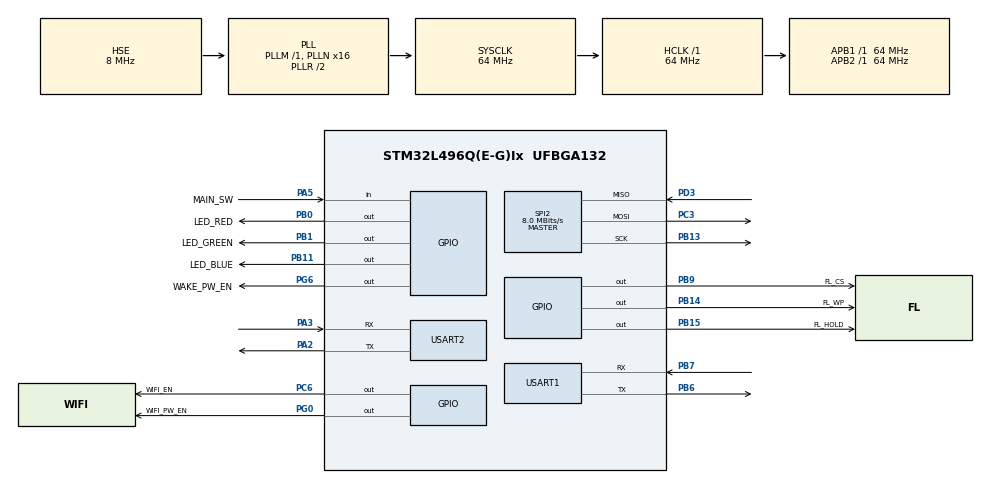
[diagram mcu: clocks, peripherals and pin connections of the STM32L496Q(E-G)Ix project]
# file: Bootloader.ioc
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Mcu.Family=STM32L4
Mcu.Name=STM32L496Q(E-G)Ix
Mcu.Package=UFBGA132
NVIC.PriorityGroup=NVIC_PRIORITYGROUP_4
NVIC.USART2_IRQn=true\:0\:0\:false\:false\:true\:true\:true\:true
PA13\ (JTMS/SWDIO).Mode=Serial_Wire
PA13\ (JTMS/SWDIO).Signal=SYS_JTMS-SWDIO
PA14\ (JTCK/SWCLK).Mode=Serial_Wire
PA14\ (JTCK/SWCLK).Signal=SYS_JTCK-SWCLK
PA2.Mode=Asynchronous
PA2.Signal=USART2_TX
PA3.Mode=Asynchronous
PA3.Signal=USART2_RX
PA5.GPIO_Label=MAIN_SW
PA5.Signal=GPIO_Input
PB0.GPIO_Label=LED_RED
PB0.Signal=GPIO_Output
PB1.GPIO_Label=LED_GREEN
PB1.Signal=GPIO_Output
PB11.GPIO_Label=LED_BLUE
PB11.GPIO_PuPd=GPIO_NOPULL
PB11.Signal=GPIO_Output
PB13.Mode=Full_Duplex_Master
PB13.Signal=SPI2_SCK
PB14.GPIO_Label=FL_WP
PB14.GPIO_PuPd=GPIO_PULLUP
PB14.GPIO_Speed=GPIO_SPEED_FREQ_HIGH
PB14.PinState=GPIO_PIN_SET
PB14.Signal=GPIO_Output
PB15.GPIO_Label=FL_HOLD
PB15.GPIO_PuPd=GPIO_PULLUP
PB15.GPIO_Speed=GPIO_SPEED_FREQ_HIGH
PB15.PinState=GPIO_PIN_SET
PB15.Signal=GPIO_Output
PB6.Mode=Asynchronous
PB6.Signal=USART1_TX
PB7.Mode=Asynchronous
PB7.Signal=USART1_RX
PB9.GPIO_Label=FL_CS
PB9.GPIO_PuPd=GPIO_PULLUP
PB9.GPIO_Speed=GPIO_SPEED_FREQ_HIGH
PB9.PinState=GPIO_PIN_SET
PB9.Signal=GPIO_Output
PC14-OSC32_IN\ (PC14).Mode=LSE-External-Oscillator
PC14-OSC32_IN\ (PC14).Signal=RCC_OSC32_IN
PC15-OSC32_OUT\ (PC15).Mode=LSE-External-Oscillator
PC15-OSC32_OUT\ (PC15).Signal=RCC_OSC32_OUT
PC3.Mode=Full_Duplex_Master
PC3.Signal=SPI2_MOSI
PC6.GPIO_Label=WIFI_EN
PC6.Signal=GPIO_Output
PD3.Mode=Full_Duplex_Master
PD3.Signal=SPI2_MISO
PG0.GPIO_Label=WIFI_PW_EN
PG0.Signal=GPIO_Output
PG6.GPIO_Label=WAKE_PW_EN
PG6.PinState=GPIO_PIN_SET
PG6.Signal=GPIO_Output
PH0-OSC_IN\ (PH0).Mode=HSE-External-Oscillator
PH0-OSC_IN\ (PH0).Signal=RCC_OSC_IN
PH1-OSC_OUT\ (PH1).Mode=HSE-External-Oscillator
PH1-OSC_OUT\ (PH1).Signal=RCC_OSC_OUT
ProjectManager.HeapSize=0x200
ProjectManager.StackSize=0x400
ProjectManager.TargetToolchain=STM32CubeIDE
RCC.ADCFreq_Value=32000000
RCC.AHBFreq_Value=64000000
RCC.APB1Freq_Value=64000000
RCC.APB1TimFreq_Value=64000000
RCC.APB2Freq_Value=64000000
RCC.APB2TimFreq_Value=64000000
RCC.CortexFreq_Value=64000000
RCC.HCLKFreq_Value=64000000
RCC.HSE_VALUE=8000000
RCC.HSI48_VALUE=48000000
RCC.HSI_VALUE=16000000
RCC.MSIAutoCalibration=DISABLED
RCC.MSI_VALUE=4000000
RCC.PLLN=16
RCC.PLLSourceVirtual=RCC_PLLSOURCE_HSE
RCC.RTCClockSelection=RCC_RTCCLKSOURCE_LSE
RCC.SYSCLKFreq_VALUE=64000000
RCC.SYSCLKSource=RCC_SYSCLKSOURCE_PLLCLK
RCC.USBFreq_Value=32000000
RCC.VCOOutputFreq_Value=128000000
SPI2.BaudRatePrescaler=SPI_BAUDRATEPRESCALER_8
SPI2.CalculateBaudRate=8.0 MBits/s
SPI2.DataSize=SPI_DATASIZE_8BIT
SPI2.Direction=SPI_DIRECTION_2LINES
SPI2.Mode=SPI_MODE_MASTER
SPI2.VirtualType=VM_MASTER
USART1.VirtualMode-Asynchronous=VM_ASYNC
USART2.Parity=PARITY_NONE
USART2.VirtualMode-Asynchronous=VM_ASYNC
USART2.WordLength=WORDLENGTH_8B
VP_CRC_VS_CRC.Mode=CRC_Activate
VP_RTC_VS_RTC_Activate.Mode=RTC_Enabled
VP_RTC_VS_RTC_Calendar.Mode=RTC_Calendar
board=custom

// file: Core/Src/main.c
/* USER CODE BEGIN Header */
/**
  ******************************************************************************
  * @file           : main.c
  * @brief          : Main program body
  ******************************************************************************
  * @attention
  *
  * Copyright (c) 2025 STMicroelectronics.
  * All rights reserved.
  *
  * This software is licensed under terms that can be found in the LICENSE file
  * in the root directory of this software component.
  * If no LICENSE file comes with this software, it is provided AS-IS.
  *
  ******************************************************************************
  */
/* USER CODE END Header */
#include "main.h"

/* USER CODE BEGIN Includes */
#include "app_main.h"
/* USER CODE END Includes */

CRC_HandleTypeDef hcrc;

RTC_HandleTypeDef hrtc;

SPI_HandleTypeDef hspi2;

UART_HandleTypeDef huart1;
UART_HandleTypeDef huart2;

void SystemClock_Config(void);
static void MX_GPIO_Init(void);
static void MX_USART1_UART_Init(void);
static void MX_USART2_UART_Init(void);
static void MX_CRC_Init(void);
static void MX_SPI2_Init(void);
static void MX_RTC_Init(void);

int main(void)
{

  /* MCU Configuration--------------------------------------------------------*/

  /* Reset of all peripherals, Initializes the Flash interface and the Systick. */
  HAL_Init();

  /* Configure the system clock */
  SystemClock_Config();

  /* Initialize all configured peripherals */
  MX_GPIO_Init();
  MX_USART1_UART_Init();
  MX_USART2_UART_Init();
  MX_CRC_Init();
  MX_SPI2_Init();
  MX_RTC_Init();
  /* USER CODE BEGIN 2 */
  app_main_init();
  /* USER CODE END 2 */

  /* Infinite loop */
  while (1)
  {

  }
}

void SystemClock_Config(void)
{
  RCC_OscInitTypeDef RCC_OscInitStruct = {0};
  RCC_ClkInitTypeDef RCC_ClkInitStruct = {0};

  /** Configure the main internal regulator output voltage
  */
  if (HAL_PWREx_ControlVoltageScaling(PWR_REGULATOR_VOLTAGE_SCALE1) != HAL_OK)
  {
    Error_Handler();
  }

  /** Configure LSE Drive Capability
  */
  HAL_PWR_EnableBkUpAccess();
  __HAL_RCC_LSEDRIVE_CONFIG(RCC_LSEDRIVE_LOW);

  /** Initializes the RCC Oscillators according to the specified parameters
  * in the RCC_OscInitTypeDef structure.
  */
  RCC_OscInitStruct.OscillatorType = RCC_OSCILLATORTYPE_HSE|RCC_OSCILLATORTYPE_LSE;
  RCC_OscInitStruct.HSEState = RCC_HSE_ON;
  RCC_OscInitStruct.LSEState = RCC_LSE_ON;
  RCC_OscInitStruct.PLL.PLLState = RCC_PLL_ON;
  RCC_OscInitStruct.PLL.PLLSource = RCC_PLLSOURCE_HSE;
  RCC_OscInitStruct.PLL.PLLM = 1;
  RCC_OscInitStruct.PLL.PLLN = 16;
  RCC_OscInitStruct.PLL.PLLP = RCC_PLLP_DIV2;
  RCC_OscInitStruct.PLL.PLLQ = RCC_PLLQ_DIV2;
  RCC_OscInitStruct.PLL.PLLR = RCC_PLLR_DIV2;
  if (HAL_RCC_OscConfig(&RCC_OscInitStruct) != HAL_OK)
  {
    Error_Handler();
  }

  /** Initializes the CPU, AHB and APB buses clocks
  */
  RCC_ClkInitStruct.ClockType = RCC_CLOCKTYPE_HCLK|RCC_CLOCKTYPE_SYSCLK
                              |RCC_CLOCKTYPE_PCLK1|RCC_CLOCKTYPE_PCLK2;
  RCC_ClkInitStruct.SYSCLKSource = RCC_SYSCLKSOURCE_PLLCLK;
  RCC_ClkInitStruct.AHBCLKDivider = RCC_SYSCLK_DIV1;
  RCC_ClkInitStruct.APB1CLKDivider = RCC_HCLK_DIV1;
  RCC_ClkInitStruct.APB2CLKDivider = RCC_HCLK_DIV1;

  if (HAL_RCC_ClockConfig(&RCC_ClkInitStruct, FLASH_LATENCY_3) != HAL_OK)
  {
    Error_Handler();
  }
}

static void MX_CRC_Init(void)
{

  hcrc.Instance = CRC;
  hcrc.Init.DefaultPolynomialUse = DEFAULT_POLYNOMIAL_ENABLE;
  hcrc.Init.DefaultInitValueUse = DEFAULT_INIT_VALUE_ENABLE;
  hcrc.Init.InputDataInversionMode = CRC_INPUTDATA_INVERSION_NONE;
  hcrc.Init.OutputDataInversionMode = CRC_OUTPUTDATA_INVERSION_DISABLE;
  hcrc.InputDataFormat = CRC_INPUTDATA_FORMAT_BYTES;
  if (HAL_CRC_Init(&hcrc) != HAL_OK)
  {
    Error_Handler();
  }

}

static void MX_RTC_Init(void)
{

  RTC_TimeTypeDef sTime = {0};
  RTC_DateTypeDef sDate = {0};

  /** Initialize RTC Only
  */
  hrtc.Instance = RTC;
  hrtc.Init.HourFormat = RTC_HOURFORMAT_24;
  hrtc.Init.AsynchPrediv = 127;
  hrtc.Init.SynchPrediv = 255;
  hrtc.Init.OutPut = RTC_OUTPUT_DISABLE;
  hrtc.Init.OutPutRemap = RTC_OUTPUT_REMAP_NONE;
  hrtc.Init.OutPutPolarity = RTC_OUTPUT_POLARITY_HIGH;
  hrtc.Init.OutPutType = RTC_OUTPUT_TYPE_OPENDRAIN;
  if (HAL_RTC_Init(&hrtc) != HAL_OK)
  {
    Error_Handler();
  }

  /** Initialize RTC and set the Time and Date
  */
  sTime.Hours = 0x0;
  sTime.Minutes = 0x0;
  sTime.Seconds = 0x0;
  sTime.DayLightSaving = RTC_DAYLIGHTSAVING_NONE;
  sTime.StoreOperation = RTC_STOREOPERATION_RESET;
  if (HAL_RTC_SetTime(&hrtc, &sTime, RTC_FORMAT_BCD) != HAL_OK)
  {
    Error_Handler();
  }
  sDate.WeekDay = RTC_WEEKDAY_MONDAY;
  sDate.Month = RTC_MONTH_JANUARY;
  sDate.Date = 0x1;
  sDate.Year = 0x0;

  if (HAL_RTC_SetDate(&hrtc, &sDate, RTC_FORMAT_BCD) != HAL_OK)
  {
    Error_Handler();
  }

}

static void MX_SPI2_Init(void)
{

  /* SPI2 parameter configuration*/
  hspi2.Instance = SPI2;
  hspi2.Init.Mode = SPI_MODE_MASTER;
  hspi2.Init.Direction = SPI_DIRECTION_2LINES;
  hspi2.Init.DataSize = SPI_DATASIZE_8BIT;
  hspi2.Init.CLKPolarity = SPI_POLARITY_LOW;
  hspi2.Init.CLKPhase = SPI_PHASE_1EDGE;
  hspi2.Init.NSS = SPI_NSS_SOFT;
  hspi2.Init.BaudRatePrescaler = SPI_BAUDRATEPRESCALER_8;
  hspi2.Init.FirstBit = SPI_FIRSTBIT_MSB;
  hspi2.Init.TIMode = SPI_TIMODE_DISABLE;
  hspi2.Init.CRCCalculation = SPI_CRCCALCULATION_DISABLE;
  hspi2.Init.CRCPolynomial = 7;
  hspi2.Init.CRCLength = SPI_CRC_LENGTH_DATASIZE;
  hspi2.Init.NSSPMode = SPI_NSS_PULSE_ENABLE;
  if (HAL_SPI_Init(&hspi2) != HAL_OK)
  {
    Error_Handler();
  }

}

static void MX_USART1_UART_Init(void)
{

  huart1.Instance = USART1;
  huart1.Init.BaudRate = 115200;
  huart1.Init.WordLength = UART_WORDLENGTH_8B;
  huart1.Init.StopBits = UART_STOPBITS_1;
  huart1.Init.Parity = UART_PARITY_NONE;
  huart1.Init.Mode = UART_MODE_TX_RX;
  huart1.Init.HwFlowCtl = UART_HWCONTROL_NONE;
  huart1.Init.OverSampling = UART_OVERSAMPLING_16;
  huart1.Init.OneBitSampling = UART_ONE_BIT_SAMPLE_DISABLE;
  huart1.AdvancedInit.AdvFeatureInit = UART_ADVFEATURE_NO_INIT;
  if (HAL_UART_Init(&huart1) != HAL_OK)
  {
    Error_Handler();
  }

}

static void MX_USART2_UART_Init(void)
{

  huart2.Instance = USART2;
  huart2.Init.BaudRate = 115200;
  huart2.Init.WordLength = UART_WORDLENGTH_8B;
  huart2.Init.StopBits = UART_STOPBITS_1;
  huart2.Init.Parity = UART_PARITY_NONE;
  huart2.Init.Mode = UART_MODE_TX_RX;
  huart2.Init.HwFlowCtl = UART_HWCONTROL_NONE;
  huart2.Init.OverSampling = UART_OVERSAMPLING_16;
  huart2.Init.OneBitSampling = UART_ONE_BIT_SAMPLE_DISABLE;
  huart2.AdvancedInit.AdvFeatureInit = UART_ADVFEATURE_NO_INIT;
  if (HAL_UART_Init(&huart2) != HAL_OK)
  {
    Error_Handler();
  }

}

static void MX_GPIO_Init(void)
{
  GPIO_InitTypeDef GPIO_InitStruct = {0};

  /* GPIO Ports Clock Enable */
  __HAL_RCC_GPIOA_CLK_ENABLE();
  __HAL_RCC_GPIOB_CLK_ENABLE();
  __HAL_RCC_GPIOD_CLK_ENABLE();
  __HAL_RCC_GPIOC_CLK_ENABLE();
  __HAL_RCC_GPIOH_CLK_ENABLE();
  __HAL_RCC_GPIOG_CLK_ENABLE();
  HAL_PWREx_EnableVddIO2();

  /*Configure GPIO pin Output Level */
  HAL_GPIO_WritePin(GPIOB, FL_CS_Pin|FL_HOLD_Pin|FL_WP_Pin, GPIO_PIN_SET);

  /*Configure GPIO pin Output Level */
  HAL_GPIO_WritePin(WIFI_EN_GPIO_Port, WIFI_EN_Pin, GPIO_PIN_RESET);

  /*Configure GPIO pin Output Level */
  HAL_GPIO_WritePin(WAKE_PW_EN_GPIO_Port, WAKE_PW_EN_Pin, GPIO_PIN_SET);

  /*Configure GPIO pin Output Level */
  HAL_GPIO_WritePin(WIFI_PW_EN_GPIO_Port, WIFI_PW_EN_Pin, GPIO_PIN_RESET);

  /*Configure GPIO pin Output Level */
  HAL_GPIO_WritePin(GPIOB, LED_BLUE_Pin|LED_RED_Pin|LED_GREEN_Pin, GPIO_PIN_RESET);

  /*Configure GPIO pins : FL_CS_Pin FL_HOLD_Pin FL_WP_Pin */
  GPIO_InitStruct.Pin = FL_CS_Pin|FL_HOLD_Pin|FL_WP_Pin;
  GPIO_InitStruct.Mode = GPIO_MODE_OUTPUT_PP;
  GPIO_InitStruct.Pull = GPIO_PULLUP;
  GPIO_InitStruct.Speed = GPIO_SPEED_FREQ_HIGH;
  HAL_GPIO_Init(GPIOB, &GPIO_InitStruct);

  /*Configure GPIO pin : WIFI_EN_Pin */
  GPIO_InitStruct.Pin = WIFI_EN_Pin;
  GPIO_InitStruct.Mode = GPIO_MODE_OUTPUT_PP;
  GPIO_InitStruct.Pull = GPIO_NOPULL;
  GPIO_InitStruct.Speed = GPIO_SPEED_FREQ_LOW;
  HAL_GPIO_Init(WIFI_EN_GPIO_Port, &GPIO_InitStruct);

  /*Configure GPIO pins : WAKE_PW_EN_Pin WIFI_PW_EN_Pin */
  GPIO_InitStruct.Pin = WAKE_PW_EN_Pin|WIFI_PW_EN_Pin;
  GPIO_InitStruct.Mode = GPIO_MODE_OUTPUT_PP;
  GPIO_InitStruct.Pull = GPIO_NOPULL;
  GPIO_InitStruct.Speed = GPIO_SPEED_FREQ_LOW;
  HAL_GPIO_Init(GPIOG, &GPIO_InitStruct);

  /*Configure GPIO pin : MAIN_SW_Pin */
  GPIO_InitStruct.Pin = MAIN_SW_Pin;
  GPIO_InitStruct.Mode = GPIO_MODE_INPUT;
  GPIO_InitStruct.Pull = GPIO_NOPULL;
  HAL_GPIO_Init(MAIN_SW_GPIO_Port, &GPIO_InitStruct);

  /*Configure GPIO pins : LED_BLUE_Pin LED_RED_Pin LED_GREEN_Pin */
  GPIO_InitStruct.Pin = LED_BLUE_Pin|LED_RED_Pin|LED_GREEN_Pin;
  GPIO_InitStruct.Mode = GPIO_MODE_OUTPUT_PP;
  GPIO_InitStruct.Pull = GPIO_NOPULL;
  GPIO_InitStruct.Speed = GPIO_SPEED_FREQ_LOW;
  HAL_GPIO_Init(GPIOB, &GPIO_InitStruct);

}

void Error_Handler(void)
{
  __disable_irq();
  while (1)
  {
  }
}
